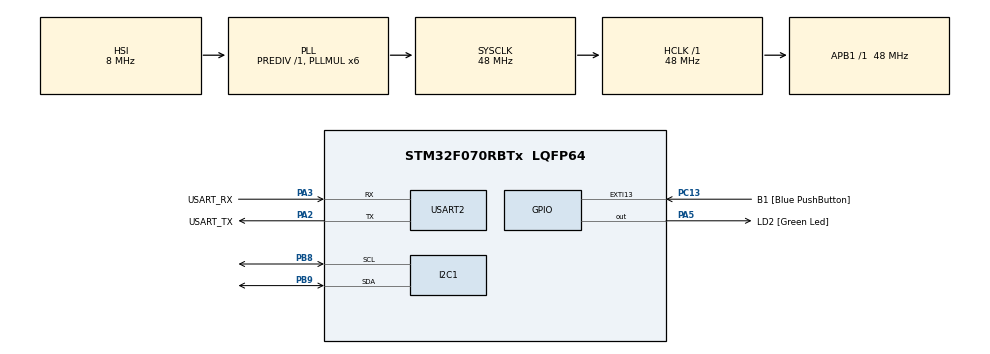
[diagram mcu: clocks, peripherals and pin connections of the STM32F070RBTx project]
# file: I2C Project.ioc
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Mcu.Family=STM32F0
Mcu.Name=STM32F070RBTx
Mcu.Package=LQFP64
PA13.GPIO_Label=TMS
PA13.Mode=Serial_Wire
PA13.Signal=SYS_SWDIO
PA14.GPIO_Label=TCK
PA14.Mode=Serial_Wire
PA14.Signal=SYS_SWCLK
PA2.GPIO_Label=USART_TX
PA2.Mode=Asynchronous
PA2.Signal=USART2_TX
PA3.GPIO_Label=USART_RX
PA3.Mode=Asynchronous
PA3.Signal=USART2_RX
PA5.GPIO_Label=LD2 [Green Led]
PA5.Signal=GPIO_Output
PB8.Mode=I2C
PB8.Signal=I2C1_SCL
PB9.Mode=I2C
PB9.Signal=I2C1_SDA
PC13.GPIO_Label=B1 [Blue PushButton]
PC13.GPIO_ModeDefaultEXTI=GPIO_MODE_IT_FALLING
PC13.Signal=GPXTI13
PC14-OSC32_IN.GPIO_Label=RCC_OSC32_IN
PC14-OSC32_IN.Mode=LSE-External-Oscillator
PC14-OSC32_IN.Signal=RCC_OSC32_IN
PC15-OSC32_OUT.GPIO_Label=RCC_OSC32_OUT
PC15-OSC32_OUT.Mode=LSE-External-Oscillator
PC15-OSC32_OUT.Signal=RCC_OSC32_OUT
PF0-OSC_IN.GPIO_Label=RCC_OSC_IN
PF0-OSC_IN.Mode=HSE-External-Clock-Source
PF0-OSC_IN.Signal=RCC_OSC_IN
PF1-OSC_OUT.GPIO_Label=RCC_OSC_OUT
PF1-OSC_OUT.Signal=RCC_OSC_OUT
ProjectManager.HeapSize=0x200
ProjectManager.StackSize=0x400
ProjectManager.TargetToolchain=STM32CubeIDE
RCC.AHBFreq_Value=48000000
RCC.APB1Freq_Value=48000000
RCC.APB1TimFreq_Value=48000000
RCC.HCLKFreq_Value=48000000
RCC.PLLMUL=RCC_PLL_MUL6
RCC.SYSCLKFreq_VALUE=48000000
RCC.SYSCLKSource=RCC_SYSCLKSOURCE_PLLCLK
USART2.VirtualMode-Asynchronous=VM_ASYNC
board=NUCLEO-F070RB

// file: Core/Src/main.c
/* USER CODE BEGIN Header */
/**
  ******************************************************************************
  * @file           : main.c
  * @brief          : Main program body
  ******************************************************************************
  * @attention
  *
  * Copyright (c) 2023 STMicroelectronics.
  * All rights reserved.
  *
  * This software is licensed under terms that can be found in the LICENSE file
  * in the root directory of this software component.
  * If no LICENSE file comes with this software, it is provided AS-IS.
  *
  ******************************************************************************
  */
/* USER CODE END Header */
#include "main.h"

/* USER CODE BEGIN Includes */
#include "adxl345.h"
#include "uart_driver.h"
#include <stdio.h>
/* USER CODE END Includes */

I2C_HandleTypeDef hi2c1;

UART_HandleTypeDef huart2;

/* USER CODE BEGIN PV */

float x,y,z;
int16_t raw_x,raw_y, raw_z;
uint8_t string[50];
uint32_t size = 0;

/* USER CODE END PV */

void SystemClock_Config(void);
static void MX_GPIO_Init(void);
static void MX_USART2_UART_Init(void);
static void MX_I2C1_Init(void);

int main(void)
{

  /* MCU Configuration--------------------------------------------------------*/

  /* Reset of all peripherals, Initializes the Flash interface and the Systick. */
  HAL_Init();

  /* Configure the system clock */
  SystemClock_Config();

  /* Initialize all configured peripherals */
  MX_GPIO_Init();
  MX_USART2_UART_Init();
  MX_I2C1_Init();
  /* USER CODE BEGIN 2 */
  UART_Init();

  adxl345_init();

  /* Infinite loop */
  while (1) {
  adxl345_get_g_values(&x, &y, &z);
  adxl345_get_raw_values(&raw_x, &raw_y, &raw_z);
  //size = sprintf(string,"X:%f Y:%f Z:%f\n",x,y,z);
  /*
   size = sprintf(string,"%d %d %d\n",raw_x,raw_y,raw_z);
   UART_send_string(string,size);
   */
  size = sprintf((char*)string, "%f %f %f\n", x, y, z);
  UART_send_byte_array(string, size);
  HAL_Delay(100);
  	}
  /* USER CODE END 2 */

  /* Infinite loop */

  /* USER CODE END 3 */
}

void SystemClock_Config(void)
{
  RCC_OscInitTypeDef RCC_OscInitStruct = {0};
  RCC_ClkInitTypeDef RCC_ClkInitStruct = {0};
  RCC_PeriphCLKInitTypeDef PeriphClkInit = {0};

  /** Initializes the RCC Oscillators according to the specified parameters
  * in the RCC_OscInitTypeDef structure.
  */
  RCC_OscInitStruct.OscillatorType = RCC_OSCILLATORTYPE_HSI;
  RCC_OscInitStruct.HSIState = RCC_HSI_ON;
  RCC_OscInitStruct.HSICalibrationValue = RCC_HSICALIBRATION_DEFAULT;
  RCC_OscInitStruct.PLL.PLLState = RCC_PLL_ON;
  RCC_OscInitStruct.PLL.PLLSource = RCC_PLLSOURCE_HSI;
  RCC_OscInitStruct.PLL.PLLMUL = RCC_PLL_MUL6;
  RCC_OscInitStruct.PLL.PREDIV = RCC_PREDIV_DIV1;
  if (HAL_RCC_OscConfig(&RCC_OscInitStruct) != HAL_OK)
  {
    Error_Handler();
  }

  /** Initializes the CPU, AHB and APB buses clocks
  */
  RCC_ClkInitStruct.ClockType = RCC_CLOCKTYPE_HCLK|RCC_CLOCKTYPE_SYSCLK
                              |RCC_CLOCKTYPE_PCLK1;
  RCC_ClkInitStruct.SYSCLKSource = RCC_SYSCLKSOURCE_PLLCLK;
  RCC_ClkInitStruct.AHBCLKDivider = RCC_SYSCLK_DIV1;
  RCC_ClkInitStruct.APB1CLKDivider = RCC_HCLK_DIV1;

  if (HAL_RCC_ClockConfig(&RCC_ClkInitStruct, FLASH_LATENCY_1) != HAL_OK)
  {
    Error_Handler();
  }
  PeriphClkInit.PeriphClockSelection = RCC_PERIPHCLK_I2C1;
  PeriphClkInit.I2c1ClockSelection = RCC_I2C1CLKSOURCE_HSI;
  if (HAL_RCCEx_PeriphCLKConfig(&PeriphClkInit) != HAL_OK)
  {
    Error_Handler();
  }
}

static void MX_I2C1_Init(void)
{

  hi2c1.Instance = I2C1;
  hi2c1.Init.Timing = 0x2000090E;
  hi2c1.Init.OwnAddress1 = 0;
  hi2c1.Init.AddressingMode = I2C_ADDRESSINGMODE_7BIT;
  hi2c1.Init.DualAddressMode = I2C_DUALADDRESS_DISABLE;
  hi2c1.Init.OwnAddress2 = 0;
  hi2c1.Init.OwnAddress2Masks = I2C_OA2_NOMASK;
  hi2c1.Init.GeneralCallMode = I2C_GENERALCALL_DISABLE;
  hi2c1.Init.NoStretchMode = I2C_NOSTRETCH_DISABLE;
  if (HAL_I2C_Init(&hi2c1) != HAL_OK)
  {
    Error_Handler();
  }

  /** Configure Analogue filter
  */
  if (HAL_I2CEx_ConfigAnalogFilter(&hi2c1, I2C_ANALOGFILTER_ENABLE) != HAL_OK)
  {
    Error_Handler();
  }

  /** Configure Digital filter
  */
  if (HAL_I2CEx_ConfigDigitalFilter(&hi2c1, 0) != HAL_OK)
  {
    Error_Handler();
  }

}

static void MX_USART2_UART_Init(void)
{

  huart2.Instance = USART2;
  huart2.Init.BaudRate = 38400;
  huart2.Init.WordLength = UART_WORDLENGTH_8B;
  huart2.Init.StopBits = UART_STOPBITS_1;
  huart2.Init.Parity = UART_PARITY_NONE;
  huart2.Init.Mode = UART_MODE_TX_RX;
  huart2.Init.HwFlowCtl = UART_HWCONTROL_NONE;
  huart2.Init.OverSampling = UART_OVERSAMPLING_16;
  huart2.Init.OneBitSampling = UART_ONE_BIT_SAMPLE_DISABLE;
  huart2.AdvancedInit.AdvFeatureInit = UART_ADVFEATURE_NO_INIT;
  if (HAL_UART_Init(&huart2) != HAL_OK)
  {
    Error_Handler();
  }

}

static void MX_GPIO_Init(void)
{
  GPIO_InitTypeDef GPIO_InitStruct = {0};

  /* GPIO Ports Clock Enable */
  __HAL_RCC_GPIOC_CLK_ENABLE();
  __HAL_RCC_GPIOF_CLK_ENABLE();
  __HAL_RCC_GPIOA_CLK_ENABLE();
  __HAL_RCC_GPIOB_CLK_ENABLE();

  /*Configure GPIO pin Output Level */
  HAL_GPIO_WritePin(LD2_GPIO_Port, LD2_Pin, GPIO_PIN_RESET);

  /*Configure GPIO pin : B1_Pin */
  GPIO_InitStruct.Pin = B1_Pin;
  GPIO_InitStruct.Mode = GPIO_MODE_IT_FALLING;
  GPIO_InitStruct.Pull = GPIO_NOPULL;
  HAL_GPIO_Init(B1_GPIO_Port, &GPIO_InitStruct);

  /*Configure GPIO pin : LD2_Pin */
  GPIO_InitStruct.Pin = LD2_Pin;
  GPIO_InitStruct.Mode = GPIO_MODE_OUTPUT_PP;
  GPIO_InitStruct.Pull = GPIO_NOPULL;
  GPIO_InitStruct.Speed = GPIO_SPEED_FREQ_LOW;
  HAL_GPIO_Init(LD2_GPIO_Port, &GPIO_InitStruct);

}

void Error_Handler(void)
{
  __disable_irq();
  while (1)
  {
  }
}
